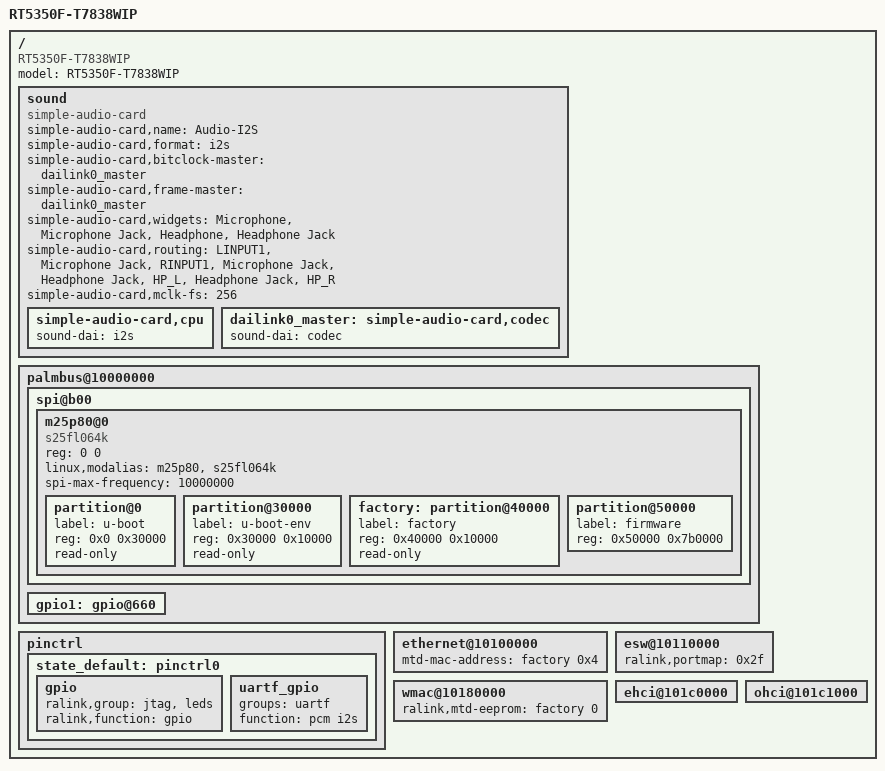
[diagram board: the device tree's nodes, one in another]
/dts-v1/;

/include/ "rt5350x.dtsi"

/ {
        compatible = "RT5350F-T7838WIP", "ralink,rt5350-soc";
        model = "RT5350F-T7838WIP";

        sound {
                compatible = "simple-audio-card";
                simple-audio-card,name = "Audio-I2S";
                simple-audio-card,format = "i2s";
                simple-audio-card,bitclock-master = <&dailink0_master>;
                simple-audio-card,frame-master = <&dailink0_master>;
                simple-audio-card,widgets =
                        "Microphone", "Microphone Jack",
                        "Headphone", "Headphone Jack";
                simple-audio-card,routing =
                        "LINPUT1", "Microphone Jack",
                        "RINPUT1", "Microphone Jack",
                        "Headphone Jack", "HP_L",
                        "Headphone Jack", "HP_R";
                simple-audio-card,mclk-fs = <256>;

                simple-audio-card,cpu {
                        sound-dai = <&i2s>;
                };

                dailink0_master: simple-audio-card,codec {
                        sound-dai = <&codec>;
                };
        };

        palmbus@10000000 {
                spi@b00 {
                        status = "okay";
                        m25p80@0 {
                                #address-cells = <1>;
                                #size-cells = <1>;
                                compatible = "s25fl064k";
                                reg = <0 0>;
                                linux,modalias = "m25p80", "s25fl064k";
                                spi-max-frequency = <10000000>;

                                partition@0 {
                                        label = "u-boot";
                                        reg = <0x0 0x30000>;
                                        read-only;
                                };

                                partition@30000 {
                                        label = "u-boot-env";
                                        reg = <0x30000 0x10000>;
                                        read-only;
                                };

                                factory: partition@40000 {
                                        label = "factory";
                                        reg = <0x40000 0x10000>;
                                        read-only;
                                };

                                partition@50000 {
                                        label = "firmware";
                                        reg = <0x50000 0x7b0000>;
                                };
                        };
                };
                gpio1: gpio@660 {
                        status = "okay";
                };
        };

        pinctrl {
                state_default: pinctrl0 {
                        gpio {
                                ralink,group = "jtag", "leds";
                                ralink,function = "gpio";
                        };
			uartf_gpio {
				groups = "uartf";
				function = "pcm i2s";
			};
                };
        };

        ethernet@10100000 {
                mtd-mac-address = <&factory 0x4>;
        };

        esw@10110000 {
                ralink,portmap = <0x2f>;
        };

        wmac@10180000 {
                ralink,mtd-eeprom = <&factory 0>;
        };

        ehci@101c0000 {
                status = "okay";
        };

        ohci@101c1000 {
                status = "okay";
        };

};


